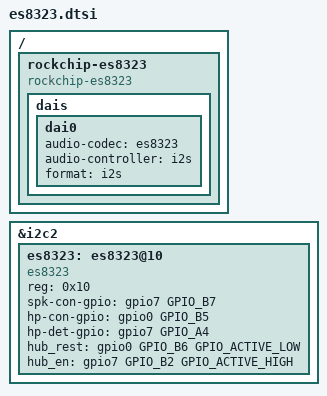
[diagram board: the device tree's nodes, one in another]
/ {
	rockchip-es8323 {
		compatible = "rockchip-es8323";
		dais {
			dai0 {
				audio-codec = <&es8323>;
				audio-controller = <&i2s>;
				format = "i2s";
			};
		};
	};
};

&i2c2 {
es8323: es8323@10 {
			compatible = "es8323";
			reg = <0x10>;
			spk-con-gpio = <&gpio7 GPIO_B7 GPIO_ACTIVE_HIGH>;
			hp-con-gpio = <&gpio0 GPIO_B5 GPIO_ACTIVE_HIGH>;
			hp-det-gpio = <&gpio7 GPIO_A4 GPIO_ACTIVE_HIGH>;
			hub_rest = <&gpio0 GPIO_B6 GPIO_ACTIVE_LOW>;
			hub_en = <&gpio7 GPIO_B2 GPIO_ACTIVE_HIGH>;
		};
};
